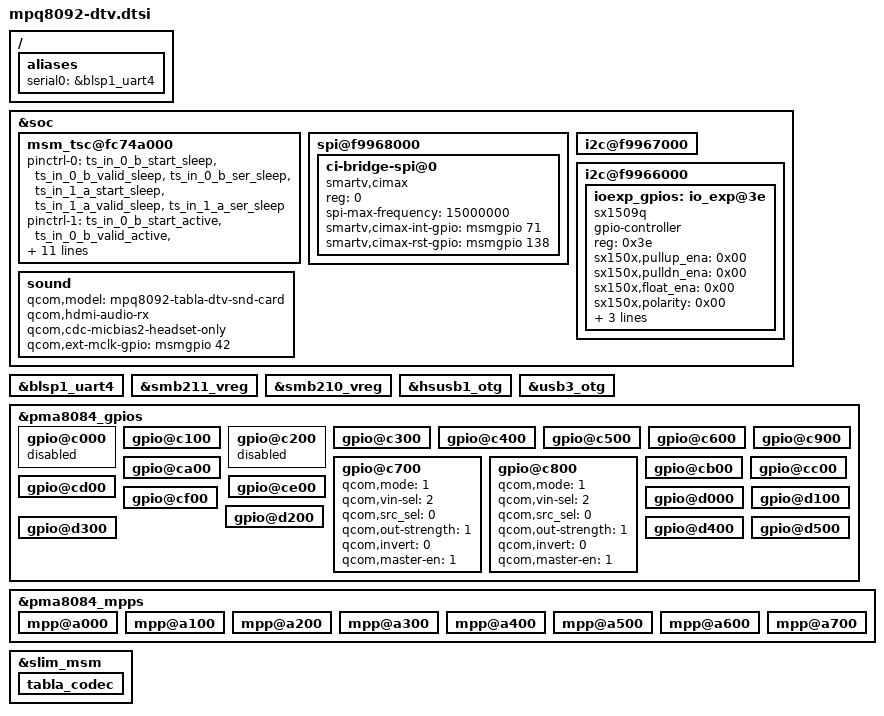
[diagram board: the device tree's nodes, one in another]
/* Copyright (c) 2013-2014, The Linux Foundation. All rights reserved.
 *
 * This program is free software; you can redistribute it and/or modify
 * it under the terms of the GNU General Public License version 2 and
 * only version 2 as published by the Free Software Foundation.
 *
 * This program is distributed in the hope that it will be useful,
 * but WITHOUT ANY WARRANTY; without even the implied warranty of
 * MERCHANTABILITY or FITNESS FOR A PARTICULAR PURPOSE.  See the
 * GNU General Public License for more details.
 */

/ {
	aliases {
		serial0 = &blsp1_uart4;
	};
};

&soc {
	msm_tsc@fc74a000 {
		pinctrl-names = "disable", "ts-in-0", "ts-in-1", "dual-ts";
		pinctrl-0 = <&ts_in_0_b_start_sleep
					&ts_in_0_b_valid_sleep
					&ts_in_0_b_ser_sleep
					&ts_in_1_a_start_sleep
					&ts_in_1_a_valid_sleep
					&ts_in_1_a_ser_sleep>;	/* disable */
		pinctrl-1 = <&ts_in_0_b_start_active
					&ts_in_0_b_valid_active
					&ts_in_0_b_ser_active
					&ts_in_1_a_start_sleep
					&ts_in_1_a_valid_sleep
					&ts_in_1_a_ser_sleep>; /* ts-in-0 */
		pinctrl-2 = <&ts_in_0_b_start_sleep
					&ts_in_0_b_valid_sleep
					&ts_in_0_b_ser_sleep
					&ts_in_1_a_start_active
					&ts_in_1_a_valid_active
					&ts_in_1_a_ser_active>;	/* ts-in-1 */
		pinctrl-3 = <&ts_in_0_b_start_active
					&ts_in_0_b_valid_active
					&ts_in_0_b_ser_active
					&ts_in_1_a_start_active
					&ts_in_1_a_valid_active
					&ts_in_1_a_ser_active>;	/* dual-ts */
	};

	spi@f9968000 {
	   ci-bridge-spi@0 {
			compatible = "smartv,cimax";
			reg = <0>;
			spi-max-frequency = <15000000>;
			smartv,cimax-int-gpio = <&msmgpio 71 0>;
			smartv,cimax-rst-gpio = <&msmgpio 138 0>;
	   };
	};

	i2c@f9967000 {
		status = "ok";
	};

	i2c@f9966000 {
		status = "ok";
	};

	i2c@f9966000 {
		ioexp_gpios: io_exp@3e {
			#gpio-cells = <2>;
                        compatible = "sx1509q";
			gpio-controller;
			reg = <0x3e>;
			sx150x,pullup_ena = <0x00>;
			sx150x,pulldn_ena = <0x00>;
			sx150x,float_ena  = <0x00>;
			sx150x,polarity = <0x00>;
			sx150x,reset_onprobe;
			sx150x,reset_gpio = <&msmgpio 37 0x00>;
			label = "ioexp-gpio";
		};
	};

	sound {
		qcom,model = "mpq8092-tabla-dtv-snd-card";
		qcom,hdmi-audio-rx;
		qcom,cdc-micbias2-headset-only;
		qcom,ext-mclk-gpio  = <&msmgpio 42 0>;
	};
};

&blsp1_uart4 {
	status = "ok";
};

&smb211_vreg {
	status = "ok";
};

&smb210_vreg {
	status = "ok";
};

&hsusb1_otg {
	status = "ok";
};

&usb3_otg {
	status = "ok";
};


&pma8084_gpios {
	gpio@c000 { /* GPIO 1 */
		/* SMB210 DBU4 5.0 V regulator enable - no software control */
		status = "disabled";
	};

	gpio@c100 { /* GPIO 2 */
	};

	gpio@c200 { /* GPIO 3 */
		/* SMB211 DBU2 3.3 V regulator enable - no software control */
		status = "disabled";
	};

	gpio@c300 { /* GPIO 4 */
	};

	gpio@c400 { /* GPIO 5 */
	};

	gpio@c500 { /* GPIO 6 */
	};

	gpio@c600 { /* GPIO 7 */
	};

	gpio@c700 { /* GPIO 8 - USB OTG 3.0 */
		qcom,mode = <1>;	/* Digital output */
		qcom,vin-sel = <2>;	/* PMA8084 S4 = 1.8V */
		qcom,src_sel = <0>;	/* Constant Function */
		qcom,out-strength = <1>;/* Low */
		qcom,invert = <0>;	/* Output low initially */
		qcom,master-en = <1>;	/* Enable GPIO */
	};

	gpio@c800 { /* GPIO 9 -  USB OTG 2.0 (Port-1) */
		qcom,mode = <1>;	/* Digital output */
		qcom,vin-sel = <2>;	/* PMA8084 S4 = 1.8V */
		qcom,src_sel = <0>;	/* Constant Function */
		qcom,out-strength = <1>;/* Low */
		qcom,invert = <0>;	/* Output low initially */
		qcom,master-en = <1>;	/* Enable GPIO */
	};

	gpio@c900 { /* GPIO 10 */
	};

	gpio@ca00 { /* GPIO 11 */
	};

	gpio@cb00 { /* GPIO 12 */
	};

	gpio@cc00 { /* GPIO 13 */
	};

	gpio@cd00 { /* GPIO 14 */
	};

	gpio@ce00 { /* GPIO 15 */
	};

	gpio@cf00 { /* GPIO 16 */
	};

	gpio@d000 { /* GPIO 17 */
	};

	gpio@d100 { /* GPIO 18 */
	};

	gpio@d200 { /* GPIO 19 */
	};

	gpio@d300 { /* GPIO 20 */
	};

	gpio@d400 { /* GPIO 21 */
	};

	gpio@d500 { /* GPIO 22 */
	};
};

&pma8084_mpps {
	mpp@a000 { /* MPP 1 */
	};

	mpp@a100 { /* MPP 2 */
	};

	mpp@a200 { /* MPP 3 */
	};

	mpp@a300 { /* MPP 4 */
	};

	mpp@a400 { /* MPP 5 */
	};

	mpp@a500 { /* MPP 6 */
	};

	mpp@a600 { /* MPP 7 */
	};

	mpp@a700 { /* MPP 8 */
	};
};

&slim_msm {
	tabla_codec {
	};
};
